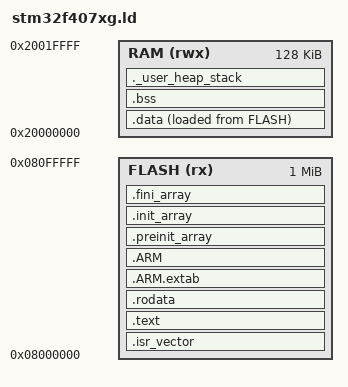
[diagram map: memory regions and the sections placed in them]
/* STM32F407xG: 1 MB flash, 128 KB system SRAM. The 64 KB CCM is not in this map. __stack_size and __heap_size come from the Makefile. */

ENTRY(Reset_Handler)

MEMORY
{
	FLASH (rx)  : ORIGIN = 0x08000000, LENGTH = 1024K
	RAM   (rwx) : ORIGIN = 0x20000000, LENGTH = 128K
}

_estack = ORIGIN(RAM) + LENGTH(RAM);

SECTIONS
{
	.isr_vector :
	{
		. = ALIGN(4);
		KEEP(*(.isr_vector))
		. = ALIGN(4);
	} > FLASH

	.text :
	{
		. = ALIGN(4);
		*(.text)
		*(.text*)
		*(.glue_7)
		*(.glue_7t)
		*(.eh_frame)
		KEEP(*(.init))
		KEEP(*(.fini))
		. = ALIGN(4);
		_etext = .;
	} > FLASH

	.rodata :
	{
		. = ALIGN(4);
		*(.rodata)
		*(.rodata*)
		. = ALIGN(4);
	} > FLASH

	.ARM.extab : { *(.ARM.extab* .gnu.linkonce.armextab.*) } > FLASH
	.ARM :
	{
		__exidx_start = .;
		*(.ARM.exidx*)
		__exidx_end = .;
	} > FLASH

	.preinit_array :
	{
		PROVIDE_HIDDEN(__preinit_array_start = .);
		KEEP(*(.preinit_array*))
		PROVIDE_HIDDEN(__preinit_array_end = .);
	} > FLASH
	.init_array :
	{
		PROVIDE_HIDDEN(__init_array_start = .);
		KEEP(*(SORT(.init_array.*)))
		KEEP(*(.init_array*))
		PROVIDE_HIDDEN(__init_array_end = .);
	} > FLASH
	.fini_array :
	{
		PROVIDE_HIDDEN(__fini_array_start = .);
		KEEP(*(SORT(.fini_array.*)))
		KEEP(*(.fini_array*))
		PROVIDE_HIDDEN(__fini_array_end = .);
	} > FLASH

	_sidata = LOADADDR(.data);

	.data :
	{
		. = ALIGN(4);
		_sdata = .;
		*(.data)
		*(.data*)
		. = ALIGN(4);
		_edata = .;
	} > RAM AT> FLASH

	.bss (NOLOAD) :
	{
		. = ALIGN(4);
		_sbss = .;
		__bss_start__ = _sbss;
		*(.bss)
		*(.bss*)
		*(COMMON)
		. = ALIGN(4);
		_ebss = .;
		__bss_end__ = _ebss;
	} > RAM

	/* newlib's _sbrk grows from end; the stack sits at the top of RAM */
	._user_heap_stack (NOLOAD) :
	{
		. = ALIGN(8);
		PROVIDE(end = .);
		PROVIDE(_end = .);
		. = . + __heap_size;
		. = . + __stack_size;
		. = ALIGN(8);
	} > RAM

	.ARM.attributes 0 : { *(.ARM.attributes) }
}
